# HDSC_HC32L176 register map
Vendor: HDSC Co.Ltd; Series: ARMCM0P; File version: 1.2
CPU: CM0 r0p0, little endian, no MPU, no FPU, 3 interrupt priority bits
Registers are 32-bit, read-write, reset 0x0 unless marked. A register's access mark holds for its fields unless they carry their own. Offsets are from the block's base; [hi:lo] are bit positions; {n}, {i} and the like mark numbered series.

## FLASH
Base 0x40020000
0x00 TNVS reset 0x20
  [8:0] TNVS
0x04 TPGS reset 0x17
  [7:0] TPGS
0x08 TPROG reset 0x1B (reset mask 0xFF)
  [8:0] TPROG
0x0C TSERASE reset 0x4650
  [17:0] TSERASE
0x10 TMERASE reset 0x222E0
  [20:0] TMERASE
0x14 TPRCV reset 0x18
  [11:0] TPRCV
0x18 TSRCV reset 0xF0
  [11:0] TSRCV
0x1C TMRCV reset 0x3E8 (reset mask 0x1FFF)
  [13:0] TMRCV
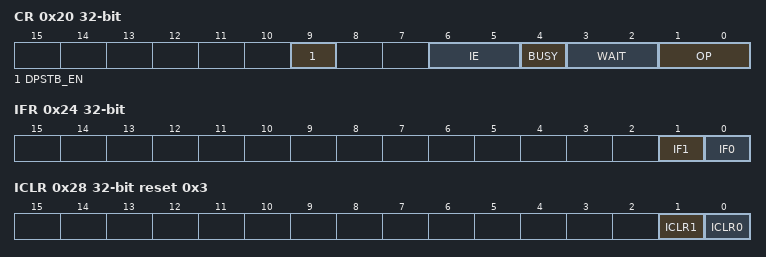
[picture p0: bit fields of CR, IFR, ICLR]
0x20 CR (reset mask 0x277)
  [9] DPSTB_EN, [6:5] IE, [4] BUSY ro, [3:2] WAIT, [1:0] OP
0x24 IFR ro
  [1] IF1, [0] IF0
0x28 ICLR wo reset 0x3
  [1] ICLR1, [0] ICLR0
0x2C BYPASS wo
  [15:0] BYSEQ
0x30 SLOCK0
  [31:0] SLOCK
0x34 SLOCK1
  [31:0] SLOCK

## HDIV
Base 0x40021800
0x00 DIVIDEND
0x04 DIVISOR reset 0x1
  [15:0] DIVISOR
0x08 QUOTIENT
0x0C REMAINDER
0x10 SIGN
  [0] SIGN
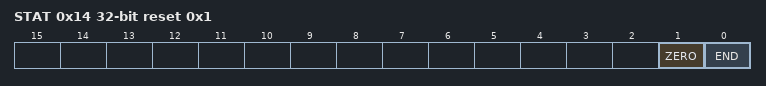
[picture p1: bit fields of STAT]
0x14 STAT reset 0x1
  [1] ZERO ro, [0] END ro

## I2C0 — desc I2C
Base 0x40000400
Same registers: I2C1 0x40004400
0x00 TMRUN
  [0] TME
0x04 TM
  [7:0] TM
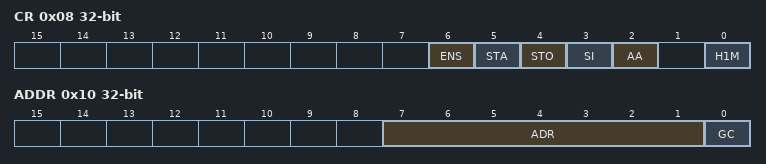
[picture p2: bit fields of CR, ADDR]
0x08 CR
  [6] ENS, [5] STA, [4] STO, [3] SI, [2] AA, [0] H1M
0x0C DATA
  [7:0] DAT
0x10 ADDR
  [7:1] ADR, [0] GC
0x14 STAT ro
  [7:0] STA

## I2S0 — desc I2S
Base 0x40002800
Same registers: I2S1 0x40002C00
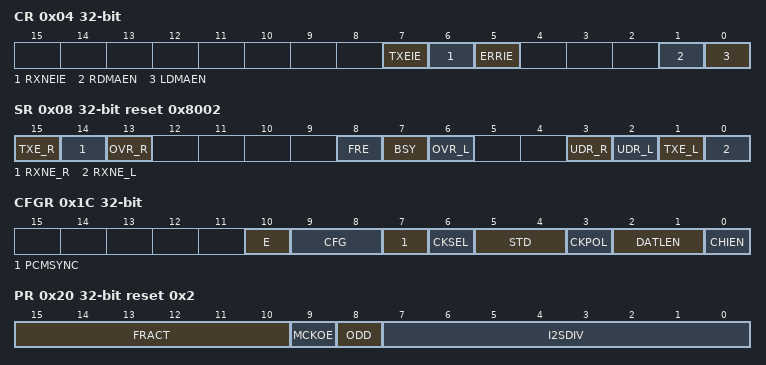
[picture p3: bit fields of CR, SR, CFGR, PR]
0x04 CR
  [7] TXEIE, [6] RXNEIE, [5] ERRIE, [1] RDMAEN, [0] LDMAEN
0x08 SR reset 0x8002
  [15] TXE_R ro, [14] RXNE_R ro, [13] OVR_R ro, [8] FRE ro, [7] BSY ro, [6] OVR_L ro, [3] UDR_R ro, [2] UDR_L ro, [1] TXE_L ro, [0] RXNE_L ro
0x1C CFGR
  [10] E, [9:8] CFG, [7] PCMSYNC, [6] CKSEL, [5:4] STD, [3] CKPOL, [2:1] DATLEN, [0] CHIEN
0x20 PR reset 0x2
  [15:10] FRACT, [9] MCKOE, [8] ODD, [7:0] I2SDIV
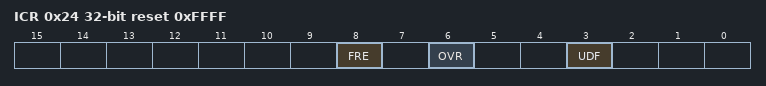
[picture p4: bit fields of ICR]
0x24 ICR reset 0xFFFF
  [8] FRE, [6] OVR, [3] UDF
0x28 DRL
  [15:0] DRL
0x2C DRR
  [15:0] DRR

## LCD
Base 0x40005C00
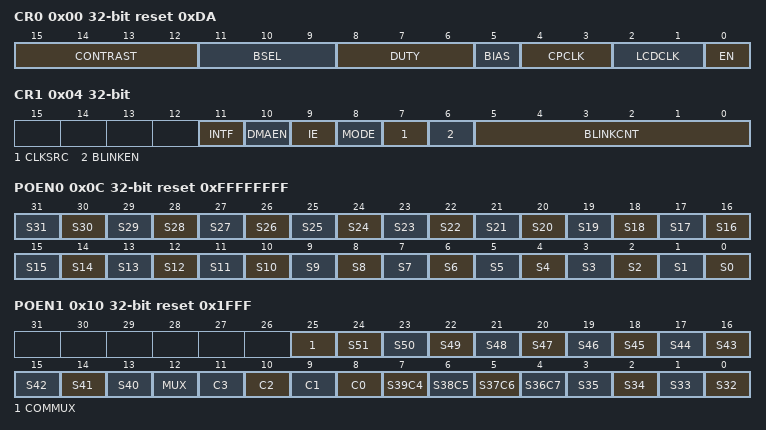
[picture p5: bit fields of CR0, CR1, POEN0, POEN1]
0x00 CR0 reset 0xDA (reset mask 0xFF)
  [15:12] CONTRAST, [11:9] BSEL, [8:6] DUTY, [5] BIAS, [4:3] CPCLK, [2:1] LCDCLK, [0] EN
0x04 CR1
  [11] INTF ro, [10] DMAEN, [9] IE, [8] MODE, [7] CLKSRC, [6] BLINKEN, [5:0] BLINKCNT
0x08 INTCLR wo
  [10] INTF
0x0C POEN0 reset 0xFFFFFFFF
  [n] S{n} (n=0..31)
0x10 POEN1 reset 0x1FFF (reset mask 0x1FFF)
  [25] COMMUX, [n-27] S{n} (n=40..51), [12] MUX, [n+8] C{n} (n=0..3), [7] S39C4, [6] S38C5, [5] S37C6, [4] S36C7, [n-32] S{n} (n=32..35)
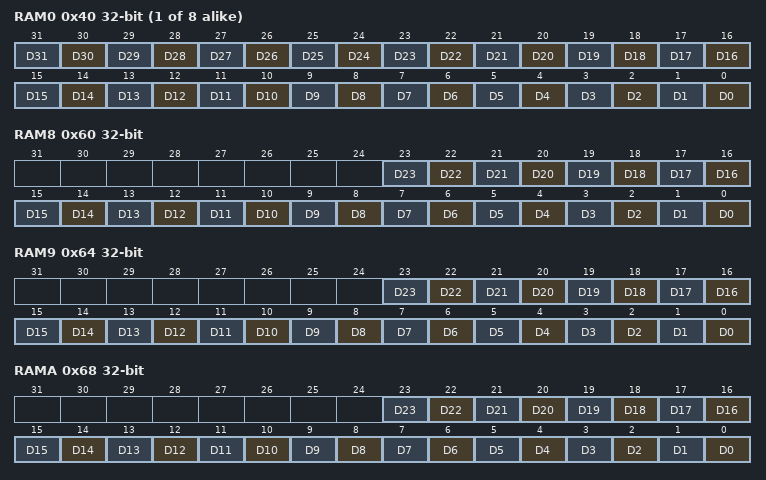
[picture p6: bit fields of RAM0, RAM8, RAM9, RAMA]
{0x40+4i} RAM{i} (i=0..7)
  [n] D{n} (n=0..31)
0x60 RAM8
  [n] D{n} (n=0..23)
0x64 RAM9
  [n] D{n} (n=0..23)
0x68 RAMA
  [n] D{n} (n=0..23)
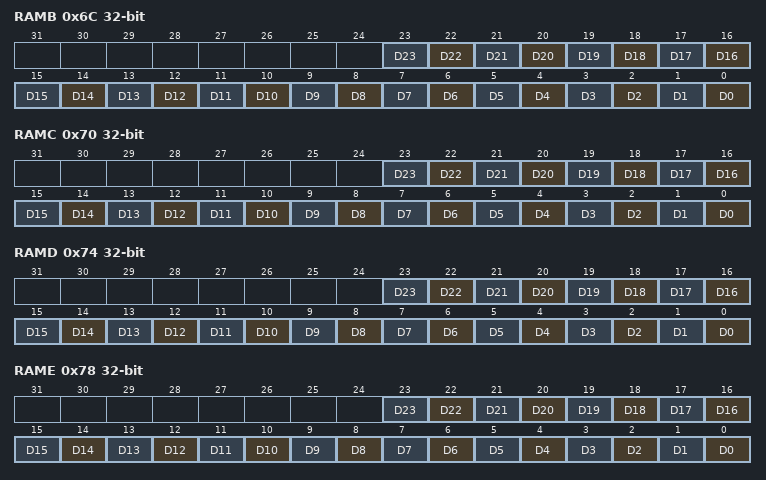
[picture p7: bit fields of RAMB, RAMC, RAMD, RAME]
0x6C RAMB
  [n] D{n} (n=0..23)
0x70 RAMC
  [n] D{n} (n=0..23)
0x74 RAMD
  [n] D{n} (n=0..23)
0x78 RAME
  [n] D{n} (n=0..23)
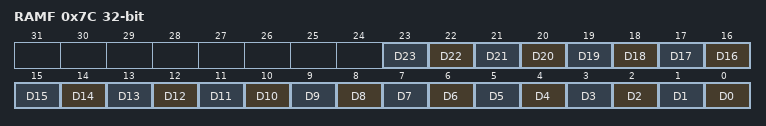
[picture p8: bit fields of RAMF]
0x7C RAMF
  [n] D{n} (n=0..23)

## LPTIMER0 — desc LPTIMER
Base 0x40000F00
Same registers: LPTIMER1 0x40000F40
0x00 CNT ro
  [15:0] CNT
0x04 ARR
  [15:0] ARR
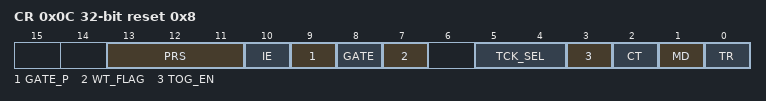
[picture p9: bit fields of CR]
0x0C CR reset 0x8
  [13:11] PRS, [10] IE, [9] GATE_P, [8] GATE, [7] WT_FLAG ro, [5:4] TCK_SEL, [3] TOG_EN, [2] CT, [1] MD, [0] TR
0x10 IFR ro
  [0] TF
0x14 ICLR wo reset 0x1
  [0] TFC

## LPUART0 — desc LPUART
Base 0x40000200
Same registers: LPUART1 0x40004000
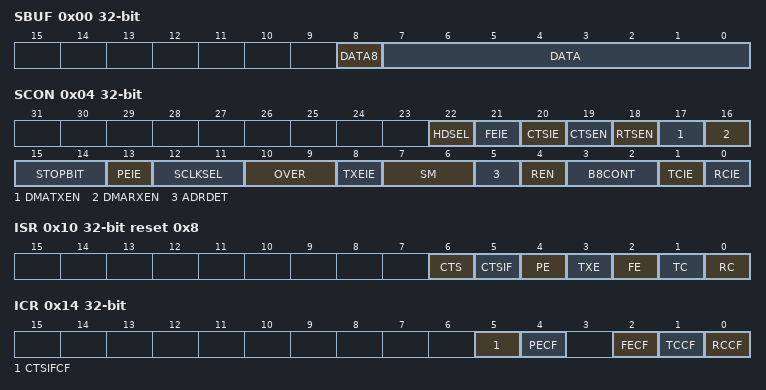
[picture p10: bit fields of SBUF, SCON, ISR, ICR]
0x00 SBUF
  [8] DATA8, [7:0] DATA
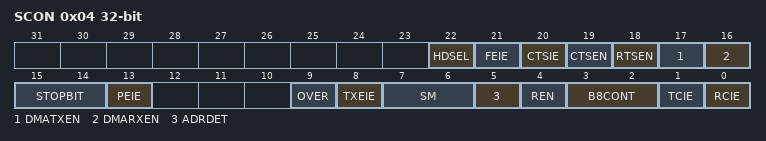
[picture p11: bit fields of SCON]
0x04 SCON
  [22] HDSEL, [21] FEIE, [20] CTSIE, [19] CTSEN, [18] RTSEN, [17] DMATXEN, [16] DMARXEN, [15:14] STOPBIT, [13] PEIE, [12:11] SCLKSEL, [10:9] OVER, [8] TXEIE, [7:6] SM, [5] ADRDET, [4] REN, [3:2] B8CONT, [1] TCIE, [0] RCIE
0x08 SADDR
  [7:0] SADDR
0x0C SADEN
  [7:0] SADEN
0x10 ISR ro reset 0x8
  [6] CTS, [5] CTSIF, [4] PE, [3] TXE, [2] FE, [1] TC, [0] RC
0x14 ICR wo
  [5] CTSIFCF, [4] PECF, [2] FECF, [1] TCCF, [0] RCCF
0x18 SCNT
  [15:0] SCNT

## UART0 — desc UART
Base 0x40000000
Same registers: UART1 0x40000100, UART2 0x40006000, UART3 0x40006400
Registers as LPUART0; these are added or differ:
0x04 SCON
  [22] HDSEL, [21] FEIE, [20] CTSIE, [19] CTSEN, [18] RTSEN, [17] DMATXEN, [16] DMARXEN, [15:14] STOPBIT, [13] PEIE, [9] OVER, [8] TXEIE, [7:6] SM, [5] ADRDET, [4] REN, [3:2] B8CONT, [1] TCIE, [0] RCIE
